# dm64lc_cslr_h3a_001 register map
Vendor: Texas Instruments
Peripheral module from a debugger description file.
Registers are 32-bit, access not given, reset 0x0 unless marked. A register's access mark holds for its fields unless they carry their own. Offsets are as the file gives them; lines under a group give offsets from that group; [hi:lo] are bit positions; {n}, {i} and the like mark numbered series; 'fields as' and 'values as' point back to an identical list; <NAME> marks a mode.

## H3A — Hardware 3A Statistics Generation (AE, AF, AWB) (spec version: 1.00.w.17)
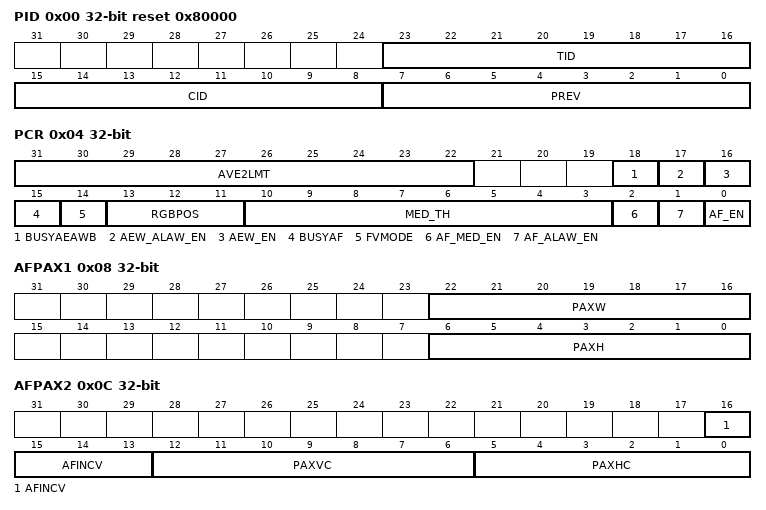
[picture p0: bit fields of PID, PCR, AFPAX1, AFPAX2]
0x00 PID reset 0x80000 (reset mask 0xFFFF00FF) — Peripheral Revision and Class Information
  [23:16] TID ro — Peripheral Identification h3A (AF, AE, and AWB)
  [15:8] CID ro — Class Identification VPFE module
  [7:0] PREV ro — Peripheral Revision Number Initial Revision
0x04 PCR (reset mask 0x3FF807) — Peripheral Control Register
  [31:22] AVE2LMT rw — AE/AWB Saturation Limit This is the value that all sub sampled pixels in the AE/AWB engine are compared to. If the data is greater or equal to this data then the block is considered saturated.
  [18] BUSYAEAWB ro — Busy bit for AE/AWB
  [17] AEW_ALAW_EN rw — AE/AWB A-law Enable
    0=DISABLE (Disable AE/AWB A-law table); 1=ENABLE (Enable AE/AWB A-law table)
  [16] AEW_EN rw — AE/AWB Enable
    0=DISABLE (Disable AE/AWB Engine); 1=ENABLE (Enable AE/AWB Engine)
  [15] BUSYAF ro — Busy bit for AF
  [14] FVMODE rw — Focus Value Accumulation Mode
    0=SUMMODE; 1=PEAKMODE
  [13:11] RGBPOS rw — Red, Green, and blue pixel location in the AF windows
    0=GR_GB_BAYER (GR and GB as Bayer pattern); 1=RG_GB_BAYER (RG and GB as Bayer pattern); 2=GR_BG_BAYER (GR and BG as Bayer pattern); 3=RG_BG_BAYER (RG and BG as Bayer pattern)
  [10:3] MED_TH rw — Median filter threshold
  [2] AF_MED_EN rw — Auto Focus Median filter Enable If the median filter is enabled, then the 1st 2 and last 2 pixels in the frame are not in the valid region. Therefore the paxel start/end and IIR filter start positions should not be set within the 1st and last 2 pixels
    0=DISABLE (Disable Auto Focus median filter); 1=ENABLE (Enable Auto Focus median filter)
  [1] AF_ALAW_EN rw — Auto Focus A-law table Enable
    0=DISABLE (Disable Auto Focus A-law table); 1=ENABLE (Enable Auto Focus A-law table)
  [0] AF_EN rw — Auto Focus Enable
    0=DISABLE (Disable Auto Focus Engine); 1=ENABLE (Enable Auto Focus Engine)
0x08 AFPAX1 — Setup for the AF Engine Paxel Configuration
  [22:16] PAXW rw — AF Engine Paxel Width The width of the paxel is the value of this register plus 1 multiplied by 2. The minimum width is 6 pixels.
  [6:0] PAXH rw — AF Engine Paxel Height The height of the paxel is the value of this register plus 1 multipled by 2 with a final value of 2-256 (even)
0x0C AFPAX2 — Setup for the AF Engine Paxel Configuration
  [16:13] AFINCV rw — AF Engine Line Increments Number of lines to increment in a Paxel plus 1 multiplied by 2. Incrementing the line in a paxel is always done on a line pair due to the fact that the RGB pattern falls in two lines. If all the lines are to be processed, this field should be set to zero, and thus line count is incremented by 2 following a line pair. Thus, the number of lines that can be skipped between two processed line pairs is 0-30 (even). The starting two lines in a paxel are first processed before this field is applied.
  [12:6] PAXVC rw — AF Engine Vertical Paxel Count The number of paxels in the vertical direction plus 1. The maximum number of vertical paxels in a frame should not exceed 128. The value should be set to ensure that the bandwidth requirements and buffer size are not exceeded.
  [5:0] PAXHC rw — AF Engine Horizontal Paxel Count The number of paxels in the horizontal direction plus 1. It is illegal to set a number that is greater than 35 (total of 36 paxels in the horizontal direction).
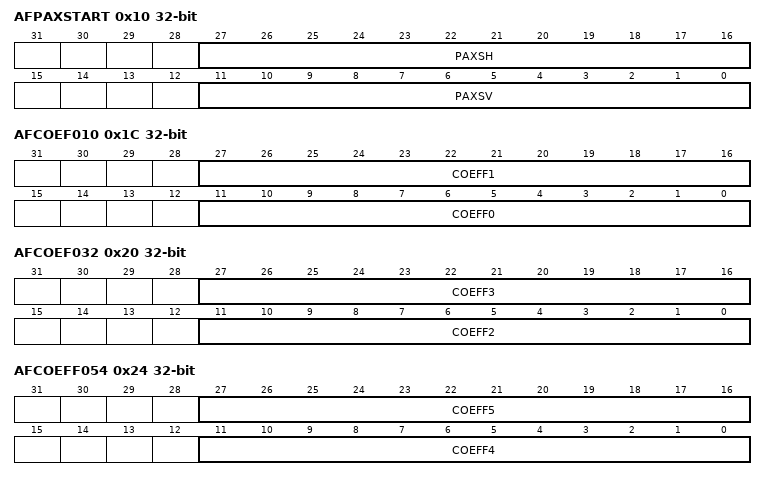
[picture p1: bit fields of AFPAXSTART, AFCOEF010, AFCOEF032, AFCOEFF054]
0x10 AFPAXSTART — Start Position for AF Engine Paxels
  [27:16] PAXSH rw — AF Engine Paxel Horizontal start position Range: 2-4094 PAXSH must be equal to or greater than (IIRSH + 2) This value must be even
  [11:0] PAXSV rw — AF Engine Paxel Vertical start position Range: 0-4095 Sets the vertical line for the first paxel.
0x14 AFIIRSH — Start Position for IIRSH
  [11:0] IIRSH rw — AF Engine IIR Horizontal Start Position Range from 0-4094. When the horizontal position of a line equals this value the shift registers are cleared on the next pixel. This value must be even
0x18 AFBUFST rw — SDRAM/DDRAM Start address for AF Engine
  [31:0] AFBUFST — AF Engine SDRAM/DDRAM Start Address The starting location in the SDRAM/DDRAM. The 6 LSB are ignored, address should be on a 64-byte boundary * This field can be altered even when the AF is busy. Change will take place only for the next frame. However, note that reading this register will always give the latest value.
0x1C AFCOEF010 — IIR filter coefficient data for SET 0
  [27:16] COEFF1 rw — AF Engine IIR filter Coefficient #1 (Set 0) The range is signed -32 <= value <= 31 +63/64
  [11:0] COEFF0 rw — AF Engine IIR filter Coefficient #0 (Set 0) The range is signed -32 <= value <= 31 +63/64
0x20 AFCOEF032 — IIR filter coefficient data for SET 0
  [27:16] COEFF3 rw — AF Engine IIR filter Coefficient #3 (Set 0) The range is signed -32 <= value <= 31 +63/64
  [11:0] COEFF2 rw — AF Engine IIR filter Coefficient #2 (Set 0) The range is signed -32 <= value <= 31 +63/64
0x24 AFCOEFF054 — IIR filter coefficient data for SET 0
  [27:16] COEFF5 rw — AF Engine IIR filter Coefficient #5 (Set 0) The range is signed -32 <= value <= 31 +63/64
  [11:0] COEFF4 rw — AF Engine IIR filter Coefficient #4 (Set 0) The range is signed -32 <= value <= 31 +63/64
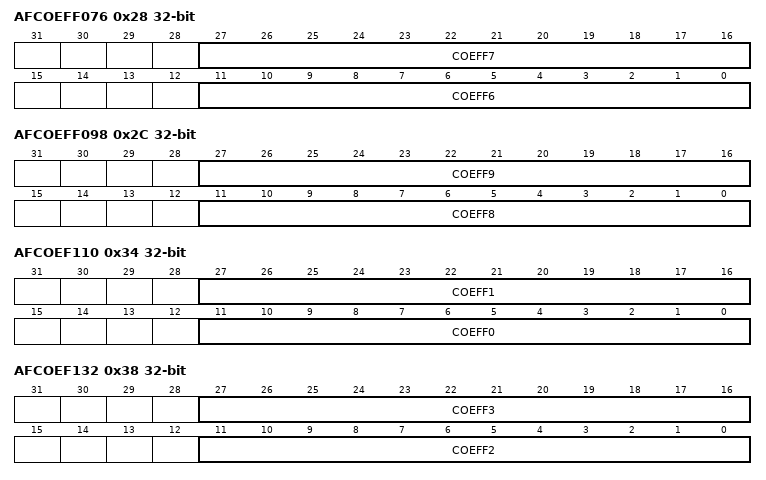
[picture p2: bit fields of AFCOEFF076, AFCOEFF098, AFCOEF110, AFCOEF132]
0x28 AFCOEFF076 — IIR filter coefficient data for SET 0
  [27:16] COEFF7 rw — AF Engine IIR filter Coefficient #7 (Set 0) The range is signed -32 <= value <= 31 +63/64
  [11:0] COEFF6 rw — AF Engine IIR filter Coefficient #6 (Set 0) The range is signed -32 <= value <= 31 +63/64
0x2C AFCOEFF098 — IIR filter coefficient data for SET 0
  [27:16] COEFF9 rw — AF Engine IIR filter Coefficient #9 (Set 0) The range is signed -32 <= value <= 31 +63/64
  [11:0] COEFF8 rw — AF Engine IIR filter Coefficient #8 (Set 0) The range is signed -32 <= value <= 31 +63/64
0x30 AFCOEFF0010 — IIR filter coefficient data for SET 0
  [11:0] COEFF10 rw — AF Engine IIR filter Coefficient #10 (Set 0) The range is signed -32 <= value <= 31 +63/64
0x34 AFCOEF110 — IIR filter coefficient data for SET 1
  [27:16] COEFF1 rw — AF Engine IIR filter Coefficient #1 (Set 1) The range is signed -32 <= value <= 31 +63/64
  [11:0] COEFF0 rw — AF Engine IIR filter Coefficient #0 (Set 1) The range is signed -32 <= value <= 31 +63/64
0x38 AFCOEF132 — IIR filter coefficient data for SET 1
  [27:16] COEFF3 rw — AF Engine IIR filter Coefficient #3 (Set 1) The range is signed -32 <= value <= 31 +63/64
  [11:0] COEFF2 rw — AF Engine IIR filter Coefficient #2 (Set 1) The range is signed -32 <= value <= 31 +63/64
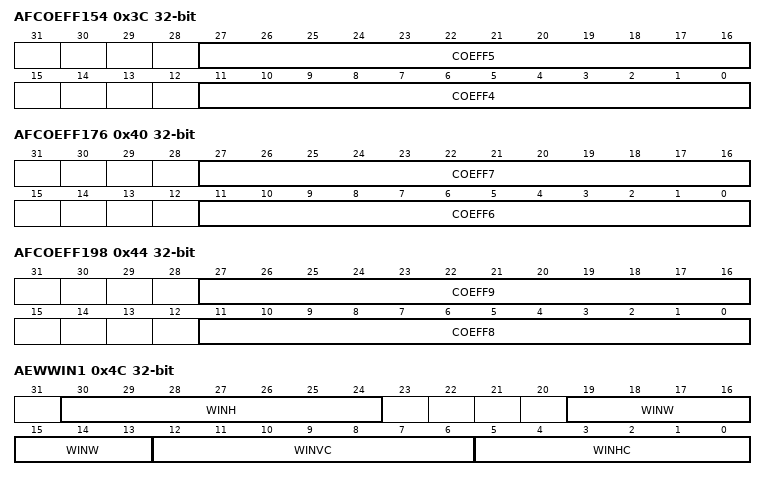
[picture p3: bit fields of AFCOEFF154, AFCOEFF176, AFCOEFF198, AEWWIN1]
0x3C AFCOEFF154 — IIR filter coefficient data for SET 1
  [27:16] COEFF5 rw — AF Engine IIR filter Coefficient #5 (Set 1) The range is signed -32 <= value <= 31 +63/64
  [11:0] COEFF4 rw — AF Engine IIR filter Coefficient #4 (Set 1) The range is signed -32 <= value <= 31 +63/64
0x40 AFCOEFF176 — IIR filter coefficient data for SET 1
  [27:16] COEFF7 rw — AF Engine IIR filter Coefficient #7 (Set 1) The range is signed -32 <= value <= 31 +63/64
  [11:0] COEFF6 rw — AF Engine IIR filter Coefficient #6 (Set 1) The range is signed -32 <= value <= 31 +63/64
0x44 AFCOEFF198 — IIR filter coefficient data for SET 1
  [27:16] COEFF9 rw — AF Engine IIR filter Coefficient #9 (Set 1) The range is signed -32 <= value <= 31 +63/64
  [11:0] COEFF8 rw — AF Engine IIR filter Coefficient #8 (Set 1) The range is signed -32 <= value <= 31 +63/64
0x48 AFCOEFF1010 — IIR filter coefficient data for SET 1
  [11:0] COEFF10 rw — AF Engine IIR filter Coefficient #10 (Set 1) The range is signed -32 <= value <= 31 +63/64
0x4C AEWWIN1 — Configuration for AE/AWB Windows
  [30:24] WINH rw — AE/AWB Engine Window Height This specifies the window height in an even number of pixels, the window height is the value plus 1 multiplied by 2. The final value can be from 2-256 (even)
  [19:13] WINW rw — AE/AWB Engine Window Width This specifies the window width in an even number of pixels, the window width is the value plus 1 multiplied by 2. The minimum width is 6 pixels.
  [12:6] WINVC rw — AE/AWB Engine Vertical Window Count The number of windows in the vertical direction plus 1. The maximum number of vertical windows in a frame should not exceed 128. The value should be set to ensure that the bandwidth requirements and buffer size are not exceeded
  [5:0] WINHC rw — AE/AWB Engine Horizontal Window Count The number of horizontal windows plus 1. The maximum number of horizontal windows is 35 plus 1 (36). The minimum number of windows should be 2 (valid range for the field is 1-35).
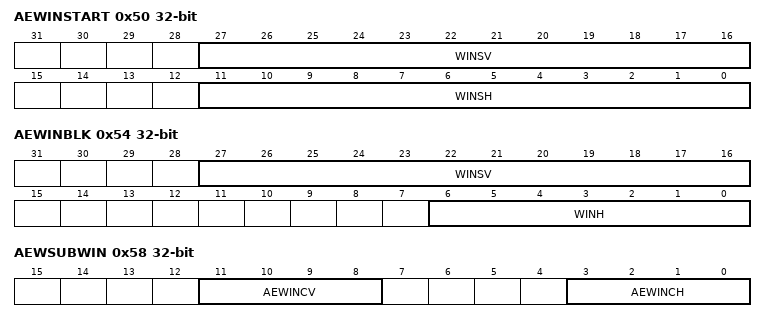
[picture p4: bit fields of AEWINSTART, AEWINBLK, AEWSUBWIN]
0x50 AEWINSTART — Start position for AE/AWB Windows
  [27:16] WINSV rw — AE/AWB Engine Vertical Window Start Position Sets the first line for the first window. Range 0-4095
  [11:0] WINSH rw — AE/AWB Engine Horizontal Window Start Position Sets the horizontal position for the first window on each line. Range 0-4095
0x54 AEWINBLK — Start position and height for black line of AE/AWB Windows
  [27:16] WINSV rw — AE/AWB Engine Vertical Window Start Position for single black line of windows Sets the first line for the single black line of windows. Range 0-4095 Note that the horizontal start and the horizontal number of windows will be similar to the regular windows
  [6:0] WINH rw — AE/AWB Engine Window Height for the single black line of windows This specifies the window height in an even number of pixels, the window height is the value plus 1 multiplied by 2. The final value can be from 2-256 (even)
0x58 AEWSUBWIN — Configuration for subsample data in AE/AWB window
  [11:8] AEWINCV rw — AE/AWB Engine Vertical Sampling Point Increment Sets vertical distance between sub-samples within a window plus 1 multiplied by 2. The final range is 2-32.
  [3:0] AEWINCH rw — AE/AWB Engine Horizontal Sampling Point Increment Sets horizontal distance between sub-samples within a window plus 1 multiplied by 2. The final range is 2-32.
0x5C AEWBUFST rw — SDRAM/DDRAM Start address for AE/AWB Engine
  [31:0] AEWBUFST — AE/AWB Engine SDRAM/DDRAM Start Address The starting location in the SDRAM/DDRAM for the AE/AWB data. The 6 LSB are ignored, address should be on a 64-byte boundary * This field can be altered even when the AE/AWB is busy. Change will take place only for the next frame. However, note that reading this register will always give the latest value.
